VERSION "HIPBNYYYYYYYYYYYYYYYYYYYYYYYYYYYYYYYYYYYYY/4/%%%/4/'%**4YYY///"

NS_ :

BS_:

BU_:

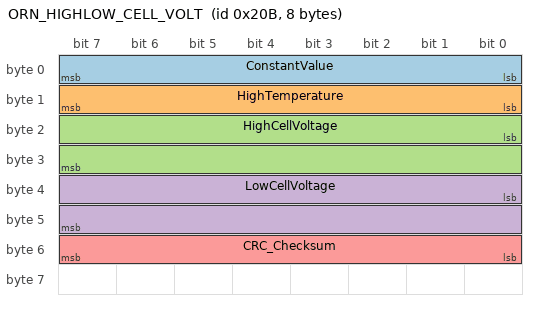
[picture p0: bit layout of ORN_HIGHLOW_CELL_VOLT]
BO_ 523 ORN_HIGHLOW_CELL_VOLT: 8 Vector__XXX
 SG_ ConstantValue : 0|8@1+ (1,0) [0|0] "" Vector__XXX
 SG_ HighTemperature : 8|8@1+ (1,0) [0|0] "" Vector__XXX
 SG_ HighCellVoltage : 16|16@1+ (1,0) [0|0] "Volts" Vector__XXX
 SG_ LowCellVoltage : 32|16@1+ (1,0) [0|0] "Volts" Vector__XXX
 SG_ CRC_Checksum : 48|8@1+ (1,0) [0|0] "" Vector__XXX
